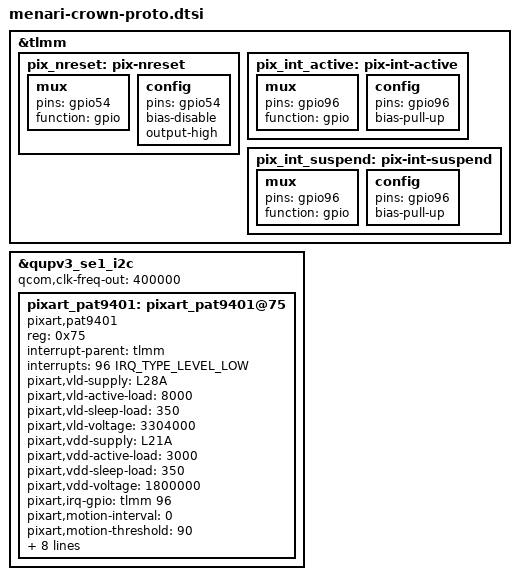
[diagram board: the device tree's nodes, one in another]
// SPDX-License-Identifier: GPL-2.0

#include <dt-bindings/interrupt-controller/irq.h>

&tlmm {
	pix_nreset: pix-nreset {
		mux {
			pins = "gpio54";
			function = "gpio";
		};
		config {
			pins = "gpio54";
			bias-disable;
			output-high;
		};
	};
	pix_int_active: pix-int-active {
		mux {
			pins = "gpio96";
			function = "gpio";
		};
		config {
			pins = "gpio96";
			bias-pull-up;
		};
	};
	pix_int_suspend: pix-int-suspend {
		mux {
			pins = "gpio96";
			function = "gpio";
		};
		config {
			pins = "gpio96";
			bias-pull-up;
		};
	};
};

&qupv3_se1_i2c {
	#address-cells = <1>;
	#size-cells = <0>;

	status = "ok";

	qcom,clk-freq-out = <400000>;

	pixart_pat9401: pixart_pat9401@75 {
		status = "okay";
		compatible = "pixart,pat9401";
		reg = <0x75>;
		interrupt-parent = <&tlmm>;
		interrupts = <96 IRQ_TYPE_LEVEL_LOW>;
		pixart,vld-supply = <&L28A>; /* VLD: L28 */
		pixart,vld-active-load = <8000>;
		pixart,vld-sleep-load = <350>;
		pixart,vld-voltage = <3304000>;
		pixart,vdd-supply = <&L21A>; /* VDD: L21 */
		pixart,vdd-active-load = <3000>;
		pixart,vdd-sleep-load = <350>;
		pixart,vdd-voltage = <1800000>;
		pixart,irq-gpio = <&tlmm 96 IRQ_TYPE_LEVEL_LOW>;
		pixart,motion-interval = <0>;
		pixart,motion-threshold = <90>;
		pixart,delay-interval = <10>;
		pixart,slop = <70>;
		pinctrl-names = "default", "sleep";
		pinctrl-0 = <&pix_int_active &pix_nreset>;
		pinctrl-1 = <&pix_int_suspend &pix_nreset>;
		display-panels = <&dsi_amb133ha01_amoled_13_cmd
		    &dsi_amb149hb01_amoled_15_cmd
		    &dsi_wj014sgm_amoled_14_cmd
		    &dsi_sim_panel_cmd>;
	};
};
